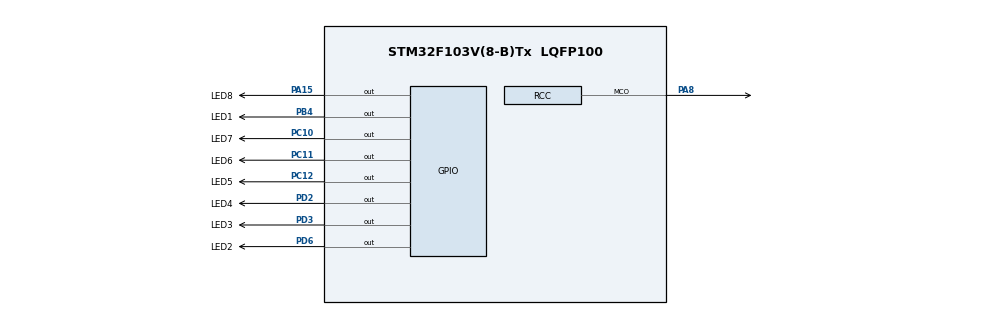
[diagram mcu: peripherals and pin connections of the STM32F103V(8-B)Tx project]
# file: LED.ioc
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Mcu.Family=STM32F1
Mcu.Name=STM32F103V(8-B)Tx
Mcu.Package=LQFP100
NVIC.PriorityGroup=NVIC_PRIORITYGROUP_4
OSC_IN.Mode=HSE-External-Oscillator
OSC_IN.Signal=RCC_OSC_IN
OSC_OUT.Mode=HSE-External-Oscillator
OSC_OUT.Signal=RCC_OSC_OUT
PA13.Mode=Serial_Wire
PA13.Signal=SYS_JTMS-SWDIO
PA14.Mode=Serial_Wire
PA14.Signal=SYS_JTCK-SWCLK
PA15.GPIO_Label=LED8
PA15.Signal=GPIO_Output
PA8.Mode=Clock-out
PA8.Signal=RCC_MCO
PB4.GPIO_Label=LED1
PB4.GPIO_PuPd=GPIO_PULLUP
PB4.GPIO_Speed=GPIO_SPEED_FREQ_HIGH
PB4.PinState=GPIO_PIN_SET
PB4.Signal=GPIO_Output
PC10.GPIO_Label=LED7
PC10.Signal=GPIO_Output
PC11.GPIO_Label=LED6
PC11.Signal=GPIO_Output
PC12.GPIO_Label=LED5
PC12.Signal=GPIO_Output
PC14-OSC32_IN.Mode=LSE-External-Oscillator
PC14-OSC32_IN.Signal=RCC_OSC32_IN
PC15-OSC32_OUT.Mode=LSE-External-Oscillator
PC15-OSC32_OUT.Signal=RCC_OSC32_OUT
PD2.GPIO_Label=LED4
PD2.GPIO_ModeDefaultOutputPP=GPIO_MODE_OUTPUT_PP
PD2.GPIO_PuPd=GPIO_PULLUP
PD2.GPIO_Speed=GPIO_SPEED_FREQ_HIGH
PD2.PinState=GPIO_PIN_SET
PD2.Signal=GPIO_Output
PD3.GPIO_Label=LED3
PD3.GPIO_ModeDefaultOutputPP=GPIO_MODE_OUTPUT_PP
PD3.GPIO_PuPd=GPIO_PULLUP
PD3.GPIO_Speed=GPIO_SPEED_FREQ_HIGH
PD3.PinState=GPIO_PIN_SET
PD3.Signal=GPIO_Output
PD6.GPIO_Label=LED2
PD6.GPIO_ModeDefaultOutputPP=GPIO_MODE_OUTPUT_PP
PD6.GPIO_PuPd=GPIO_PULLUP
PD6.GPIO_Speed=GPIO_SPEED_FREQ_HIGH
PD6.PinState=GPIO_PIN_SET
PD6.Signal=GPIO_Output
ProjectManager.HeapSize=0x200
ProjectManager.StackSize=0x400
ProjectManager.TargetToolchain=Makefile
RCC.APB1Freq_Value=8000000
RCC.APB2Freq_Value=8000000
board=custom

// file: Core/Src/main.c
/* USER CODE BEGIN Header */
/**
 ******************************************************************************
 * @file           : main.c
 * @brief          : Main program body
 ******************************************************************************
 * @attention
 *
 * Copyright (c) 2024 STMicroelectronics.
 * All rights reserved.
 *
 * This software is licensed under terms that can be found in the LICENSE file
 * in the root directory of this software component.
 * If no LICENSE file comes with this software, it is provided AS-IS.
 *
 ******************************************************************************
 */
/* USER CODE END Header */
#include "main.h"
#include "gpio.h"

void SystemClock_Config(void);

int main(void)
{

  /* MCU Configuration--------------------------------------------------------*/

  /* Reset of all peripherals, Initializes the Flash interface and the Systick. */
  HAL_Init();

  /* Configure the system clock */
  SystemClock_Config();

  /* Initialize all configured peripherals */
  MX_GPIO_Init();

  /* Infinite loop */
  /* USER CODE BEGIN WHILE */
  while (1)
  {
    // 添加代码，点亮LED0，LED1
    HAL_GPIO_WritePin(LED1_GPIO_Port, LED1_Pin, GPIO_PIN_RESET);
    HAL_GPIO_WritePin(LED2_GPIO_Port, LED2_Pin, GPIO_PIN_RESET);
    // 流水灯
    HAL_GPIO_TogglePin(LED1_GPIO_Port, LED1_Pin); // 切换亮、灭状态
    HAL_Delay(500);                               // 延时500ms
    HAL_GPIO_TogglePin(LED2_GPIO_Port, LED2_Pin); // 切换亮、灭状态
    HAL_Delay(500);                               // 延时500ms
    /* USER CODE END WHILE */

  }
}

void SystemClock_Config(void)
{
  RCC_OscInitTypeDef RCC_OscInitStruct = {0};
  RCC_ClkInitTypeDef RCC_ClkInitStruct = {0};

  /** Initializes the RCC Oscillators according to the specified parameters
   * in the RCC_OscInitTypeDef structure.
   */
  RCC_OscInitStruct.OscillatorType = RCC_OSCILLATORTYPE_HSI;
  RCC_OscInitStruct.HSIState = RCC_HSI_ON;
  RCC_OscInitStruct.HSICalibrationValue = RCC_HSICALIBRATION_DEFAULT;
  RCC_OscInitStruct.PLL.PLLState = RCC_PLL_NONE;
  if (HAL_RCC_OscConfig(&RCC_OscInitStruct) != HAL_OK)
  {
    Error_Handler();
  }

  /** Initializes the CPU, AHB and APB buses clocks
   */
  RCC_ClkInitStruct.ClockType = RCC_CLOCKTYPE_HCLK | RCC_CLOCKTYPE_SYSCLK | RCC_CLOCKTYPE_PCLK1 | RCC_CLOCKTYPE_PCLK2;
  RCC_ClkInitStruct.SYSCLKSource = RCC_SYSCLKSOURCE_HSI;
  RCC_ClkInitStruct.AHBCLKDivider = RCC_SYSCLK_DIV1;
  RCC_ClkInitStruct.APB1CLKDivider = RCC_HCLK_DIV1;
  RCC_ClkInitStruct.APB2CLKDivider = RCC_HCLK_DIV1;

  if (HAL_RCC_ClockConfig(&RCC_ClkInitStruct, FLASH_LATENCY_0) != HAL_OK)
  {
    Error_Handler();
  }
  HAL_RCC_MCOConfig(RCC_MCO, RCC_MCO1SOURCE_SYSCLK, RCC_MCODIV_1);
}

void Error_Handler(void)
{
  __disable_irq();
  while (1)
  {
  }
}
